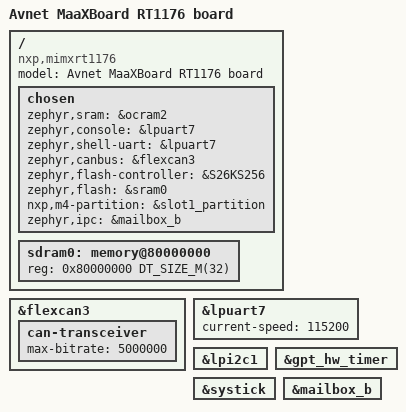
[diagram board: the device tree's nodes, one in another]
/*
 * Copyright 2021,2023 NXP
 * Copyright 2024 Avnet
 *
 * SPDX-License-Identifier: Apache-2.0
 */

/dts-v1/;

#include <nxp/nxp_rt11xx_cm4.dtsi>
#include "maax_imxrt1176.dtsi"

/ {
	model = "Avnet MaaXBoard RT1176 board";
	compatible = "nxp,mimxrt1176";

	chosen {
	zephyr,sram = &ocram2;
	zephyr,console = &lpuart7;
	zephyr,shell-uart = &lpuart7;
	zephyr,canbus = &flexcan3;
    zephyr,flash-controller = &S26KS256;
    zephyr,flash = &sram0;
    nxp,m4-partition = &slot1_partition;
    zephyr,ipc = &mailbox_b;
	};

	sdram0: memory@80000000 {
		device_type = "memory";
		reg = <0x80000000 DT_SIZE_M(32)>;
	};
};

&flexcan3 {
	status = "okay";
	can-transceiver {
		max-bitrate = <5000000>;
	};
};

&lpuart7 {
	status = "okay";
	current-speed = <115200>;
};

&lpi2c1 {
	status = "okay";
};

/* GPT and Systick are both enabled. If power management is enabled, GPT
 * will be used instead of systick as it allows the core clock to be gated.
 */
&gpt_hw_timer {
	status = "okay";
};

&systick {
	status = "okay";
};

&mailbox_b {
	status = "okay";
};
